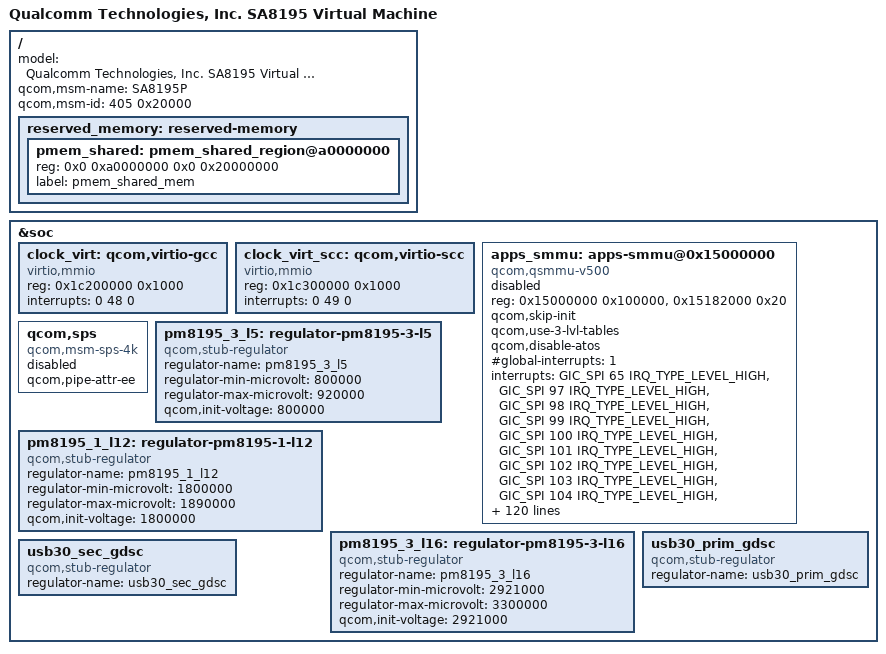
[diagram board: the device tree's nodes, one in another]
/* Copyright (c) 2019, The Linux Foundation. All rights reserved.
 *
 * This program is free software; you can redistribute it and/or modify
 * it under the terms of the GNU General Public License version 2 and
 * only version 2 as published by the Free Software Foundation.
 *
 * This program is distributed in the hope that it will be useful,
 * but WITHOUT ANY WARRANTY; without even the implied warranty of
 * MERCHANTABILITY or FITNESS FOR A PARTICULAR PURPOSE.  See the
 * GNU General Public License for more details.
 */

#include "skeleton64.dtsi"
#include <dt-bindings/clock/qcom,gcc-sdmshrike.h>
#include <dt-bindings/clock/qcom,scc-sm8150.h>
#include <dt-bindings/interrupt-controller/arm-gic.h>
#include "quin-vm-common.dtsi"

/ {
	model = "Qualcomm Technologies, Inc. SA8195 Virtual Machine";
	qcom,msm-name = "SA8195P";
	qcom,msm-id = <405 0x20000>;

	reserved_memory: reserved-memory {

		pmem_shared: pmem_shared_region@a0000000 {
			reg = <0x0 0xa0000000 0x0 0x20000000>;
			label = "pmem_shared_mem";
		};
	};
};

&soc {
	clock_virt: qcom,virtio-gcc {
		compatible = "virtio,mmio";
		reg = <0x1c200000 0x1000>;
		interrupts = <0 48 0>;
		#clock-cells = <1>;
		#reset-cells = <1>;
	};

	clock_virt_scc: qcom,virtio-scc {
		compatible = "virtio,mmio";
		reg = <0x1c300000 0x1000>;
		interrupts = <0 49 0>;
		#clock-cells = <1>;
	};

	apps_smmu: apps-smmu@0x15000000 {
		compatible = "qcom,qsmmu-v500";
		reg = <0x15000000 0x100000>,
			<0x15182000 0x20>;
		reg-names = "base", "tcu-base";
		#iommu-cells = <2>;
		qcom,skip-init;
		qcom,use-3-lvl-tables;
		qcom,disable-atos;
		#global-interrupts = <1>;
		#size-cells = <1>;
		#address-cells = <1>;
		ranges;
		interrupts =	<GIC_SPI 65 IRQ_TYPE_LEVEL_HIGH>,
				<GIC_SPI 97 IRQ_TYPE_LEVEL_HIGH>,
				<GIC_SPI 98 IRQ_TYPE_LEVEL_HIGH>,
				<GIC_SPI 99 IRQ_TYPE_LEVEL_HIGH>,
				<GIC_SPI 100 IRQ_TYPE_LEVEL_HIGH>,
				<GIC_SPI 101 IRQ_TYPE_LEVEL_HIGH>,
				<GIC_SPI 102 IRQ_TYPE_LEVEL_HIGH>,
				<GIC_SPI 103 IRQ_TYPE_LEVEL_HIGH>,
				<GIC_SPI 104 IRQ_TYPE_LEVEL_HIGH>,
				<GIC_SPI 105 IRQ_TYPE_LEVEL_HIGH>,
				<GIC_SPI 106 IRQ_TYPE_LEVEL_HIGH>,
				<GIC_SPI 107 IRQ_TYPE_LEVEL_HIGH>,
				<GIC_SPI 108 IRQ_TYPE_LEVEL_HIGH>,
				<GIC_SPI 109 IRQ_TYPE_LEVEL_HIGH>,
				<GIC_SPI 110 IRQ_TYPE_LEVEL_HIGH>,
				<GIC_SPI 111 IRQ_TYPE_LEVEL_HIGH>,
				<GIC_SPI 112 IRQ_TYPE_LEVEL_HIGH>,
				<GIC_SPI 113 IRQ_TYPE_LEVEL_HIGH>,
				<GIC_SPI 114 IRQ_TYPE_LEVEL_HIGH>,
				<GIC_SPI 115 IRQ_TYPE_LEVEL_HIGH>,
				<GIC_SPI 116 IRQ_TYPE_LEVEL_HIGH>,
				<GIC_SPI 117 IRQ_TYPE_LEVEL_HIGH>,
				<GIC_SPI 118 IRQ_TYPE_LEVEL_HIGH>,
				<GIC_SPI 181 IRQ_TYPE_LEVEL_HIGH>,
				<GIC_SPI 182 IRQ_TYPE_LEVEL_HIGH>,
				<GIC_SPI 183 IRQ_TYPE_LEVEL_HIGH>,
				<GIC_SPI 184 IRQ_TYPE_LEVEL_HIGH>,
				<GIC_SPI 185 IRQ_TYPE_LEVEL_HIGH>,
				<GIC_SPI 186 IRQ_TYPE_LEVEL_HIGH>,
				<GIC_SPI 187 IRQ_TYPE_LEVEL_HIGH>,
				<GIC_SPI 188 IRQ_TYPE_LEVEL_HIGH>,
				<GIC_SPI 189 IRQ_TYPE_LEVEL_HIGH>,
				<GIC_SPI 190 IRQ_TYPE_LEVEL_HIGH>,
				<GIC_SPI 191 IRQ_TYPE_LEVEL_HIGH>,
				<GIC_SPI 192 IRQ_TYPE_LEVEL_HIGH>,
				<GIC_SPI 315 IRQ_TYPE_LEVEL_HIGH>,
				<GIC_SPI 316 IRQ_TYPE_LEVEL_HIGH>,
				<GIC_SPI 317 IRQ_TYPE_LEVEL_HIGH>,
				<GIC_SPI 318 IRQ_TYPE_LEVEL_HIGH>,
				<GIC_SPI 319 IRQ_TYPE_LEVEL_HIGH>,
				<GIC_SPI 320 IRQ_TYPE_LEVEL_HIGH>,
				<GIC_SPI 321 IRQ_TYPE_LEVEL_HIGH>,
				<GIC_SPI 322 IRQ_TYPE_LEVEL_HIGH>,
				<GIC_SPI 323 IRQ_TYPE_LEVEL_HIGH>,
				<GIC_SPI 324 IRQ_TYPE_LEVEL_HIGH>,
				<GIC_SPI 325 IRQ_TYPE_LEVEL_HIGH>,
				<GIC_SPI 326 IRQ_TYPE_LEVEL_HIGH>,
				<GIC_SPI 327 IRQ_TYPE_LEVEL_HIGH>,
				<GIC_SPI 328 IRQ_TYPE_LEVEL_HIGH>,
				<GIC_SPI 329 IRQ_TYPE_LEVEL_HIGH>,
				<GIC_SPI 330 IRQ_TYPE_LEVEL_HIGH>,
				<GIC_SPI 331 IRQ_TYPE_LEVEL_HIGH>,
				<GIC_SPI 332 IRQ_TYPE_LEVEL_HIGH>,
				<GIC_SPI 333 IRQ_TYPE_LEVEL_HIGH>,
				<GIC_SPI 334 IRQ_TYPE_LEVEL_HIGH>,
				<GIC_SPI 335 IRQ_TYPE_LEVEL_HIGH>,
				<GIC_SPI 336 IRQ_TYPE_LEVEL_HIGH>,
				<GIC_SPI 337 IRQ_TYPE_LEVEL_HIGH>,
				<GIC_SPI 338 IRQ_TYPE_LEVEL_HIGH>,
				<GIC_SPI 339 IRQ_TYPE_LEVEL_HIGH>,
				<GIC_SPI 340 IRQ_TYPE_LEVEL_HIGH>,
				<GIC_SPI 341 IRQ_TYPE_LEVEL_HIGH>,
				<GIC_SPI 342 IRQ_TYPE_LEVEL_HIGH>,
				<GIC_SPI 343 IRQ_TYPE_LEVEL_HIGH>,
				<GIC_SPI 344 IRQ_TYPE_LEVEL_HIGH>,
				<GIC_SPI 345 IRQ_TYPE_LEVEL_HIGH>,
				<GIC_SPI 395 IRQ_TYPE_LEVEL_HIGH>,
				<GIC_SPI 396 IRQ_TYPE_LEVEL_HIGH>,
				<GIC_SPI 397 IRQ_TYPE_LEVEL_HIGH>,
				<GIC_SPI 398 IRQ_TYPE_LEVEL_HIGH>,
				<GIC_SPI 399 IRQ_TYPE_LEVEL_HIGH>,
				<GIC_SPI 400 IRQ_TYPE_LEVEL_HIGH>,
				<GIC_SPI 401 IRQ_TYPE_LEVEL_HIGH>,
				<GIC_SPI 402 IRQ_TYPE_LEVEL_HIGH>,
				<GIC_SPI 403 IRQ_TYPE_LEVEL_HIGH>,
				<GIC_SPI 404 IRQ_TYPE_LEVEL_HIGH>,
				<GIC_SPI 405 IRQ_TYPE_LEVEL_HIGH>,
				<GIC_SPI 406 IRQ_TYPE_LEVEL_HIGH>,
				<GIC_SPI 407 IRQ_TYPE_LEVEL_HIGH>,
				<GIC_SPI 408 IRQ_TYPE_LEVEL_HIGH>,
				<GIC_SPI 409 IRQ_TYPE_LEVEL_HIGH>,
				<GIC_SPI 410 IRQ_TYPE_LEVEL_HIGH>,
				<GIC_SPI 411 IRQ_TYPE_LEVEL_HIGH>,
				<GIC_SPI 412 IRQ_TYPE_LEVEL_HIGH>,
				<GIC_SPI 413 IRQ_TYPE_LEVEL_HIGH>,
				<GIC_SPI 641 IRQ_TYPE_LEVEL_HIGH>,
				<GIC_SPI 642 IRQ_TYPE_LEVEL_HIGH>,
				<GIC_SPI 643 IRQ_TYPE_LEVEL_HIGH>,
				<GIC_SPI 644 IRQ_TYPE_LEVEL_HIGH>,
				<GIC_SPI 707 IRQ_TYPE_LEVEL_HIGH>,
				<GIC_SPI 708 IRQ_TYPE_LEVEL_HIGH>,
				<GIC_SPI 709 IRQ_TYPE_LEVEL_HIGH>,
				<GIC_SPI 710 IRQ_TYPE_LEVEL_HIGH>,
				<GIC_SPI 711 IRQ_TYPE_LEVEL_HIGH>,
				<GIC_SPI 712 IRQ_TYPE_LEVEL_HIGH>,
				<GIC_SPI 713 IRQ_TYPE_LEVEL_HIGH>,
				<GIC_SPI 714 IRQ_TYPE_LEVEL_HIGH>,
				<GIC_SPI 715 IRQ_TYPE_LEVEL_HIGH>,
				<GIC_SPI 716 IRQ_TYPE_LEVEL_HIGH>,
				<GIC_SPI 769 IRQ_TYPE_LEVEL_HIGH>,
				<GIC_SPI 770 IRQ_TYPE_LEVEL_HIGH>,
				<GIC_SPI 771 IRQ_TYPE_LEVEL_HIGH>,
				<GIC_SPI 772 IRQ_TYPE_LEVEL_HIGH>,
				<GIC_SPI 773 IRQ_TYPE_LEVEL_HIGH>,
				<GIC_SPI 774 IRQ_TYPE_LEVEL_HIGH>,
				<GIC_SPI 775 IRQ_TYPE_LEVEL_HIGH>,
				<GIC_SPI 776 IRQ_TYPE_LEVEL_HIGH>,
				<GIC_SPI 777 IRQ_TYPE_LEVEL_HIGH>,
				<GIC_SPI 778 IRQ_TYPE_LEVEL_HIGH>,
				<GIC_SPI 779 IRQ_TYPE_LEVEL_HIGH>,
				<GIC_SPI 780 IRQ_TYPE_LEVEL_HIGH>,
				<GIC_SPI 781 IRQ_TYPE_LEVEL_HIGH>,
				<GIC_SPI 782 IRQ_TYPE_LEVEL_HIGH>,
				<GIC_SPI 783 IRQ_TYPE_LEVEL_HIGH>,
				<GIC_SPI 784 IRQ_TYPE_LEVEL_HIGH>,
				<GIC_SPI 785 IRQ_TYPE_LEVEL_HIGH>,
				<GIC_SPI 786 IRQ_TYPE_LEVEL_HIGH>,
				<GIC_SPI 787 IRQ_TYPE_LEVEL_HIGH>,
				<GIC_SPI 788 IRQ_TYPE_LEVEL_HIGH>,
				<GIC_SPI 789 IRQ_TYPE_LEVEL_HIGH>,
				<GIC_SPI 790 IRQ_TYPE_LEVEL_HIGH>,
				<GIC_SPI 791 IRQ_TYPE_LEVEL_HIGH>,
				<GIC_SPI 792 IRQ_TYPE_LEVEL_HIGH>,
				<GIC_SPI 793 IRQ_TYPE_LEVEL_HIGH>,
				<GIC_SPI 794 IRQ_TYPE_LEVEL_HIGH>,
				<GIC_SPI 795 IRQ_TYPE_LEVEL_HIGH>,
				<GIC_SPI 796 IRQ_TYPE_LEVEL_HIGH>,
				<GIC_SPI 797 IRQ_TYPE_LEVEL_HIGH>,
				<GIC_SPI 798 IRQ_TYPE_LEVEL_HIGH>;

		status = "disabled";
	};

	qcom,sps {
		compatible = "qcom,msm-sps-4k";
		qcom,pipe-attr-ee;
		status = "disabled";
	};

	pm8195_3_l5: regulator-pm8195-3-l5 {
		compatible = "qcom,stub-regulator";
		regulator-name = "pm8195_3_l5";
		regulator-min-microvolt = <800000>;
		regulator-max-microvolt = <920000>;
		qcom,init-voltage = <800000>;
		status = "ok";
	};

	pm8195_1_l12: regulator-pm8195-1-l12 {
		compatible = "qcom,stub-regulator";
		regulator-name = "pm8195_1_l12";
		regulator-min-microvolt = <1800000>;
		regulator-max-microvolt = <1890000>;
		qcom,init-voltage = <1800000>;
		status = "ok";
	};

	pm8195_3_l16: regulator-pm8195-3-l16 {
		compatible = "qcom,stub-regulator";
		regulator-name = "pm8195_3_l16";
		regulator-min-microvolt = <2921000>;
		regulator-max-microvolt = <3300000>;
		qcom,init-voltage = <2921000>;
		status = "ok";
	};

	usb30_prim_gdsc: usb30_prim_gdsc {
		compatible = "qcom,stub-regulator";
		regulator-name = "usb30_prim_gdsc";
		status = "okay";
	};

	usb30_sec_gdsc: usb30_sec_gdsc {
		compatible = "qcom,stub-regulator";
		regulator-name = "usb30_sec_gdsc";
		status = "okay";
	};
};

#include "sdmshrike-pinctrl.dtsi"
#include "sm8150-slpi-pinctrl.dtsi"
#include "sa8155-vm-qupv3.dtsi"
#include "sa8195-vm-usb.dtsi"
#include "sa8155-vm-audio.dtsi"
